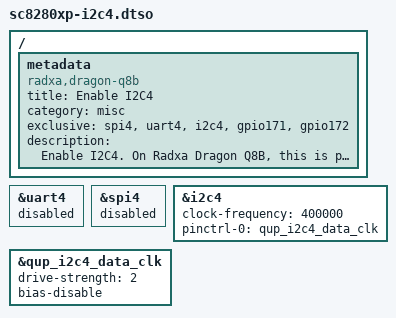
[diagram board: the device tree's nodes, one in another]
// SPDX-License-Identifier: BSD-3-Clause
/*
 * Copyright (c) 2026 Radxa Computer (Shenzhen) Co., Ltd.
 */

/dts-v1/;
/plugin/;

/ {
	metadata {
		title = "Enable I2C4";
		compatible = "radxa,dragon-q8b";
		category = "misc";
		exclusive = "spi4", "uart4", "i2c4", "gpio171", "gpio172";
		description = "Enable I2C4.
On Radxa Dragon Q8B, this is pin 38(scl), 35(sda).";
	};
};

&uart4 {
	status = "disabled";
};

&spi4 {
	status = "disabled";
};

&i2c4 {
	clock-frequency = <400000>;

	pinctrl-0 = <&qup_i2c4_data_clk>;
	pinctrl-names = "default";

	status = "okay";
};

&qup_i2c4_data_clk {
	drive-strength = <2>;
	bias-disable;
};
